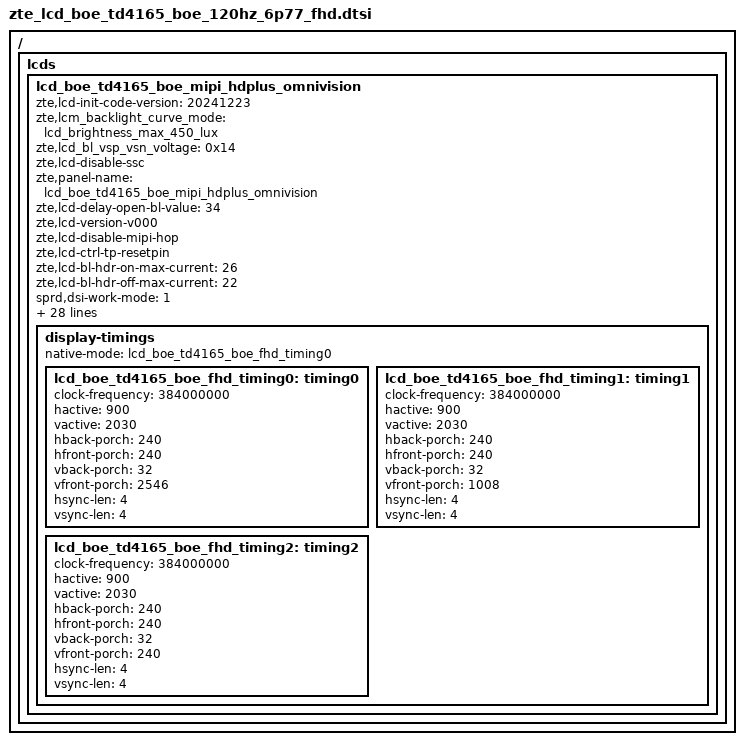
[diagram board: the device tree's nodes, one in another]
/ {
	fragment {
		target-path = "/";
		__overlay__ {
			lcds {
				lcd_boe_td4165_boe_mipi_hdplus_omnivision: lcd_boe_td4165_boe_mipi_hdplus_omnivision {
					zte,lcd-init-code-version = "20241223";

					zte,lcm_backlight_curve_mode = "lcd_brightness_max_450_lux";
					zte,lcd_bl_vsp_vsn_voltage = <0x14>;
					zte,lcd-disable-ssc;
					zte,panel-name = "lcd_boe_td4165_boe_mipi_hdplus_omnivision";
					zte,lcd-delay-open-bl-value = <34>;
					zte,lcd-version-v000;
					zte,lcd-disable-mipi-hop;
					zte,lcd-ctrl-tp-resetpin;
					zte,lcd-bl-hdr-on-max-current = <26>;
					zte,lcd-bl-hdr-off-max-current = <22>;

					sprd,dsi-work-mode = <1>;
					sprd,dsi-lane-number = <4>;
					sprd,dsi-color-format = "dsc";
					sprd,phy-bit-clock = <1100000>;
					sprd,phy-escape-clock = <20000>;/* kHz */

					sprd,width-mm = <6966>;
					sprd,height-mm = <15712>;
					sprd,vrr-enabled;
					sprd,vrr-max-layers = <3>;
					sprd,slice-width = <450>;
					sprd,slice-height = <10>;
					sprd,output-bpc = <8>;
					sprd,dsc-enable = <1>;
					sprd,dual-dsi-enable = <0>;

					sprd,esd-check-enable = <1>;/* 0:close , 1:open */
					sprd,esd-check-mode = <1>;/* 0:REG ,1:TE  */
					sprd,esd-check-period = <2000>;
					sprd,esd-check-register = <0x0A>;
					sprd,esd-check-value = <0x9C>;

					sprd,dphy-taget-val = <5>;

					sprd,reset-on-sequence = <1 5>, <0 15>, <1 20>;
					sprd,reset-off-sequence = <0 20>;

					sprd,use-gen-write;
					sprd,initial-command = [
39 00 00 02 B0 80
39 00 00 02 D6 00
39 00 00 11 B6 30 6b 00 86 91 03 13 1A 00 00 0A 0A 00 20 FF FF
39 00 00 05 B7 31 00 00 00
39 00 00 07 B8 00 78 64 10 64 b4
39 00 00 07 B9 00 78 64 10 64 b4
39 00 00 07 BA 00 78 64 10 64 b4
39 00 00 04 BB 00 b4 a0
39 00 00 04 BC 00 b4 a0
39 00 00 04 BD 00 b4 a0
39 00 00 0E BE 07 00 00 00 00 00 00 00 00 00 00 00 00
39 00 00 10 C0 00 5a 00 24 07 ee 00 00 0a 00 00 08 00 a2 00
39 00 00 3B C1 30 11 50 fa 00 00 00 22 00 00 00 00 40 0f 00 00 00 00 00 00 00 00 00 00 00 00 00 00 00 00 00 00 43 FF F5 84 7A 0A 00 20 00 00 00 00 00 00 00 00 00 00 00 00 01 08 01 10 00 00
39 00 00 E7 C2 00 60 5a 12 08 10 14 10 01 30 00 60 5a 12 08 10 10 10 00 00 00 00 00 00 00 00 00 00 00 00 00 00 00 00 00 00 00 00 00 00 00 00 00 00 00 00 05 90 49 10 10 08 09 c9 00 f0 01 00 00 00 08 11 00 f0 01 10 00 00 00 00 00 00 00 00 00 00 00 00 00 00 00 00 00 00 00 00 00 00 00 11 00 00 00 00 00 00 00 00 00 00 00 00 00 00 00 00 00 00 00 00 00 00 00 00 00 00 00 11 00 00 00 00 00 00 00 00 00 00 00 00 00 00 00 00 00 00 00 00 00 00 00 00 00 00 00 11 00 00 00 00 00 00 00 00 00 00 00 00 00 00 00 00 00 00 00 00 00 00 00 00 00 00 00 00 00 00 00 00 00 00 00 00 00 00 00 10 00 00 00 00 00 00 00 00 00 00 00 00 00 00 00 02 00 00 00 00 00 00 00 00 00 02 00 00 00 00 00 00 00 00 00 00 00 00 00 00 00 00 00 00
39 00 00 58 C3 00 a0 4a c1 01 50 09 00 00 00 20 00 00 00 00 01 00 00 00 00 00 00 23 00 04 00 4a c1 01 00 09 00 00 00 22 00 00 a0 4a c1 01 50 09 00 00 00 20 00 00 00 00 08 00 00 00 00 00 00 00 00 00 00 00 00 00 00 00 00 00 00 00 00 00 00 00 00 00 00 00 00 00 00 00 00 00 00 00
39 00 00 55 C4 00 04 0C 04 40 42 44 46 48 4A 4C 4E 0B 10 14 02 02 02 02 02 02 02 02 02 02 02 02 02 02 02 02 15 11 0B 4F 4D 4B 49 47 45 43 41 04 0C 04 00 00 00 00 00 00 F8 07 00 00 FE 01 00 00 00 00 00 00 00 00 00 00 00 00 0f 00 00 00 55 55 55 55 55 55 55 55 55 55 55
39 00 00 52 C6 00 00 00 00 01 22 04 22 01 00 46 00 00 00 01 00 46 00 01 05 01 0b 01 35 ff 0f 06 15 01 c0 01 00 00 00 00 00 00 00 00 00 00 00 00 00 00 00 00 00 00 00 00 00 00 20 20 00 00 00 c0 11 00 00 00 10 10 00 00 00 01 00 50 00 33 03 00 00 00 00 00 00 00
39 00 00 4D C7 00 00 00 1D 00 5D 00 8F 00 E4 01 0C 01 0B 01 22 01 2F 01 45 01 5A 01 6D 01 84 01 81 01 9F 02 2E 02 67 02 A4 02 B2 00 00 00 1D 00 5D 00 8F 00 E4 01 0C 01 0B 01 22 01 2F 01 45 01 5A 01 6D 01 84 01 81 01 9F 02 2E 02 67 02 A4 02 B2
39 00 00 25 CB 03 84 01 c0 00 00 00 00 00 00 00 00 00 00 00 00 00 00 00 00 00 00 40 70 00 00 00 00 00 ff 10 00 00 00 00 00
39 00 00 03 CC 89 40
39 00 00 19 CE 5d 40 43 49 55 62 71 82 94 a8 b9 cb db e9 f5 fc ff 04 00 04 04 00 00 00
39 00 00 03 CF 00 00
39 00 00 16 D0 c4 5a 81 66 09 90 00 de 92 9f 54 46 06 7e 09 08 dc 1b f0 06 06
39 00 00 2A D1 C8 d8 1b F3 33 17 07 bb 55 55 55 55 00 33 77 07 33 30 06 72 33 13 50 DB 0c 55 b2 00 18 70 18 33 73 37 33 20 20 12 00 05 05
39 00 00 05 D4 00 00 00 00
39 00 00 39 D7 21 00 12 12 00 5a 08 58 00 5a 08 58 03 83 80 85 85 85 87 84 85 86 87 80 88 87 89 83 83 87 84 88 90 8C 0B 0A EA EA E7 E7 06 06 00 08 09 0A 00 80 73 04 00 00 00 00 00 00
39 00 00 17 D8 40 99 26 ed 16 6c 16 6c 16 6c 00 14 00 14 00 14 01 0c 70 00 01 00
39 00 00 29 D9 00 02 7f 00 00 00 00 00 00 00 00 00 00 00 00 c0 00 00 00 00 00 00 00 00 00 00 00 00 00 00 00 00 00 00 00 00 00 00 00 00
39 00 00 05 DD 30 06 23 65
39 00 00 11 DE 00 00 00 0f ff 00 00 00 00 10 00 00 00 00 00 60
39 00 00 09 E6 00 00 00 00 00 00 00 00
39 00 00 5C E7 11 00 89 30 80 07 ee 03 84 00 0a 01 c2 01 c2 02 00 01 e1 20 00 d8 00 06 0c 0a ab 0c 34 18 00 10 f0 03 0c 20 00 06 0b 0b 33 0e 1c 2a 38 46 54 62 69 70 77 79 7b 7d 7e 01 02 01 00 09 40 09 be 19 fc 19 fa 19 f8 1a 38 1a 78 1a b6 2a f6 2b 34 2b 74 3b 74 6b f4 00 00 00 00 00 00
39 00 00 24 EA 02 07 07 04 80 10 01 00 00 00 00 03 23 00 07 00 ed 00 ed 00 ed 01 28 01 28 00 47 00 47 00 47 01 0f 01 00
39 00 00 19 EB 0d c0 dc 00 01 00 01 01 00 CC CC 0C 08 06 D8 00 00 00 00 00 00 00 00 00
39 00 00 18 EC 02 d0 10 70 00 00 00 00 00 00 00 02 2a 00 00 00 00 00 00 00 00 00 00
39 00 00 22 ED 01 02 00 00 00 00 00 00 00 00 dc 00 00 00 00 00 00 00 00 00 00 00 02 b0 00 00 00 00 00 00 40 10 00
39 00 00 74 EE 05 40 15 00 c0 bf 00 c0 bf 00 00 03 00 00 03 00 c0 bf 00 00 00 00 00 00 03 00 00 00 00 00 00 03 00 00 00 00 00 00 03 00 00 00 00 00 00 03 40 c0 bf 00 00 00 00 00 c0 bf 00 00 00 00 00 c0 bf 00 00 00 00 00 d5 bf 00 00 00 00 00 00 03 00 00 03 00 00 03 00 00 03 00 00 03 00 00 00 00 00 00 00 00 00 00 00 00 00 00 00 00 00 00 00 00 00 00 00 00 00 02
39 00 00 02 35 00
39 5a 00 02 11 00
39 0a 00 02 29 00
39 00 00 03 C1 30 81
39 05 00 02 B0 83
					];

					sprd,sleep-in-command = [
						15 0A 00 01 28
						15 C8 00 01 10
						];
					sprd,sleep-out-command = [
						05 78 00 01 11
						05 14 00 01 29
						];
					display-timings {
						native-mode = <&lcd_boe_td4165_boe_fhd_timing0>;
						lcd_boe_td4165_boe_fhd_timing0: timing0 {
							clock-frequency = <384000000>;
							hactive = <900>;
							vactive = <2030>;
							hback-porch = <240>;
							hfront-porch = <240>;
							vback-porch = <32>;
							vfront-porch = <2546>;
							hsync-len = <4>;
							vsync-len = <4>;
						};
						lcd_boe_td4165_boe_fhd_timing1: timing1 {
							clock-frequency = <384000000>;
							hactive = <900>;
							vactive = <2030>;
							hback-porch = <240>;
							hfront-porch = <240>;
							vback-porch = <32>;
							vfront-porch = <1008>;
							hsync-len = <4>;
							vsync-len = <4>;
						};
						lcd_boe_td4165_boe_fhd_timing2: timing2 {
							clock-frequency = <384000000>;
							hactive = <900>;
							vactive = <2030>;
							hback-porch = <240>;
							hfront-porch = <240>;
							vback-porch = <32>;
							vfront-porch = <240>;
							hsync-len = <4>;
							vsync-len = <4>;
						};
					};					
				};
			};
		};
	};
};
